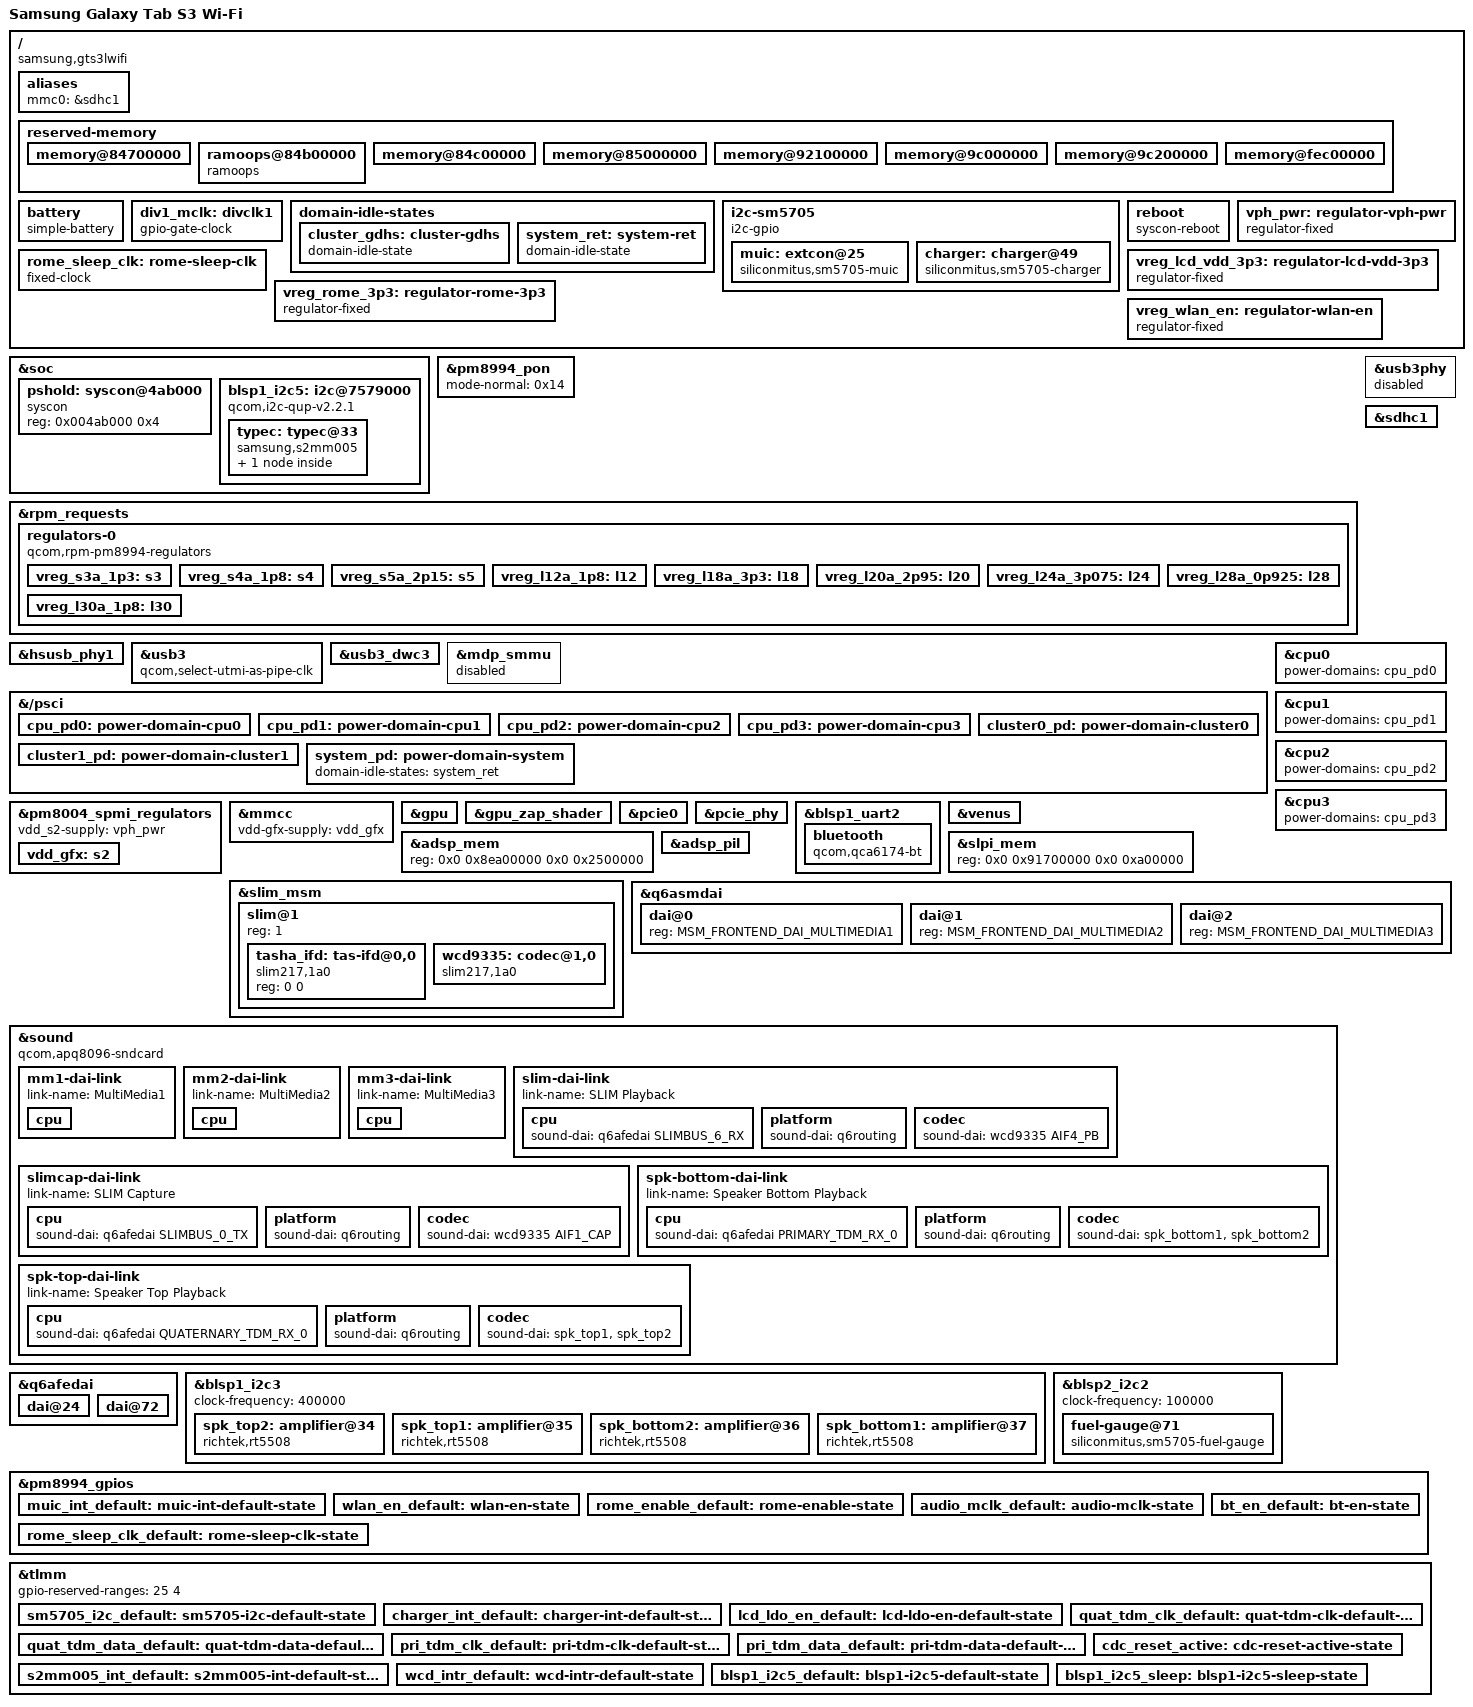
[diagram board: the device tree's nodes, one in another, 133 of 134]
// SPDX-License-Identifier: BSD-3-Clause
/*
 * Samsung Galaxy Tab S3 Wi-Fi (SM-T820), codename gts3lwifi, board rev 05
 *
 * SoC / PMIC set, from the live downstream DTB (qcom,pmic-id = <0x20009 0x1000c>):
 *   APQ8096 (msm-id 291) + PM8994 + PM8004. No PMI8994, no modem.
 * Internal storage: eMMC on SDHC1 (cmdline: androidboot.bootdevice=7464900.sdhci).
 *   UFS silicon is present but unpopulated; ufshc/ufsphy stay disabled.
 *
 * Working: eMMC, USB peripheral, reboot, GPU (headless, boot with
 * msm.separate_gpu_kms=1), Wi-Fi and Bluetooth (QCA6174), Venus, audio
 * (ADSP + WCD9335: headphones and microphones), SM5705 fuel gauge, charger
 * and MUIC, CPU/cluster/system idle. The panel, touch, speakers, sensors and
 * S-Pen are not here yet; the panel and touch have test DTs.
 *
 * GPU zap shader, Venus and ADSP firmware are Samsung-signed and come from
 * the device (apnhlos and modem partitions), under
 * qcom/apq8096/samsung/gts3lwifi/.
 *
 * Sources (all cross-checked against the live DTB with phandles resolved):
 *   downstream arch/arm64/boot/dts/samsung/msm8996-sec-gts3lwifi-r05.dts{,i}
 *   downstream arch/arm64/boot/dts/samsung/msm8996-pinctrl-sec-gts3lwifi-r05.dtsi
 *   downstream arch/arm64/boot/dts/samsung/msm8996-sec-common.dtsi
 *   downstream arch/arm64/boot/dts/samsung/msm8996-sm5705.dtsi
 *   downstream arch/arm64/boot/dts/qcom/msm8996-pm.dtsi (idle StateIDs)
 */

/dts-v1/;

#include <dt-bindings/gpio/gpio.h>
#include <dt-bindings/interrupt-controller/irq.h>
#include <dt-bindings/pinctrl/qcom,pmic-gpio.h>
#include <dt-bindings/sound/qcom,q6afe.h>
#include <dt-bindings/sound/qcom,q6asm.h>
#include <dt-bindings/sound/qcom,wcd9335.h>
#include "msm8996.dtsi"
#include "pm8994.dtsi"
#include "pm8004.dtsi"

/ {
	model = "Samsung Galaxy Tab S3 Wi-Fi";
	compatible = "samsung,gts3lwifi", "qcom,apq8096";
	chassis-type = "tablet";

	/*
	 * Bootloader DTB-selection IDs (documented in arm/qcom.yaml).
	 * lk2nd matches the root compatible instead, so these only matter
	 * if the DTB is ever offered to the stock bootloader.
	 */
	qcom,msm-id = <291 0x30001>;
	qcom,board-id = <8 5>;

	aliases {
		mmc0 = &sdhc1;
	};

	/*
	 * No memory@ node on purpose: msm8996.dtsi carries the placeholder
	 * and lk2nd rewrites it from the DDR partition table. The live DTB
	 * shows 0x80000000 + 2 GiB and 0x100000000 + 0x7e5e0000, i.e. 4 GiB
	 * with a hole - hardcoding a flat 4 GiB at 0x80000000 overshoots.
	 */

	/*
	 * Fixed regions from the downstream tree that msm8996.dtsi does not
	 * already cover. hyp/xbl/smem/tz (0x85800000-0x88800000) and the PIL
	 * regions (0x88800000-0x91700000) in msm8996.dtsi are subsets of the
	 * downstream removed/modem/peripheral carve-outs, so they are kept
	 * as they are and only the gaps are added here.
	 */
	reserved-memory {
		/* Downstream ss_plog@84700000 */
		memory@84700000 {
			reg = <0x0 0x84700000 0x0 0x400000>;
			no-map;
		};

		/* Same slot and layout as downstream ramoops@84B00000 */
		ramoops@84b00000 {
			compatible = "ramoops";
			reg = <0x0 0x84b00000 0x0 0x100000>;
			record-size = <0x40000>;
			console-size = <0x40000>;
			ftrace-size = <0x40000>;
			pmsg-size = <0x40000>;
		};

		/* Downstream lk_region@0 */
		memory@84c00000 {
			reg = <0x0 0x84c00000 0x0 0x400000>;
			no-map;
		};

		/*
		 * Samsung sec_debug: sec_dbg=0x1ff000@0x85000000 and
		 * sec_log=0x200000@0x85200000 on the downstream cmdline.
		 * S-Boot reads this back in upload mode, keep it untouched.
		 */
		memory@85000000 {
			reg = <0x0 0x85000000 0x0 0x400000>;
			no-map;
		};

		/*
		 * Tail of the downstream peripheral_region@8f400000
		 * (0x8f400000-0x92500000) not covered by msm8996.dtsi. adsp_mem
		 * is grown and slpi_mem moved into 0x91700000-0x92100000 below,
		 * so only the last 4 MiB are left.
		 */
		memory@92100000 {
			reg = <0x0 0x92100000 0x0 0x400000>;
			no-map;
		};

		/*
		 * The bootloader framebuffer (downstream cont_splash_mem,
		 * 0x9a400000, 28 MiB) is not reserved here: lk2nd adds its own
		 * reservation for it when lk2nd.pass-simplefb is used, and the
		 * two would overlap.
		 */

		/* Samsung TIMA (KNOX EL2), downstream tima_region@9C000000 */
		memory@9c000000 {
			reg = <0x0 0x9c000000 0x0 0x200000>;
			no-map;
		};

		/* Samsung RKP (KNOX EL2), downstream rkp_region@0x9C200000 */
		memory@9c200000 {
			reg = <0x0 0x9c200000 0x0 0xf00000>;
			no-map;
		};

		/* Pool handed to TrustZone, downstream qseecom_mem */
		memory@fec00000 {
			reg = <0x0 0xfec00000 0x0 0x1400000>;
			no-map;
		};
	};

	/*
	 * EB-BT825ABE, 6000 mAh, 3.85 V. Stock charges to 4.30 V
	 * (battery,chg_float_voltage), tops off at 300 mA, powers off
	 * around 3.4 V (battery0,tem_poff) and stops charging outside
	 * 0-50 C (battery,temp_{low,high}_threshold_normal).
	 */
	battery: battery {
		compatible = "simple-battery";
		device-chemistry = "lithium-ion";
		charge-full-design-microamp-hours = <6000000>;
		energy-full-design-microwatt-hours = <23100000>;
		voltage-min-design-microvolt = <3400000>;
		voltage-max-design-microvolt = <4300000>;
		constant-charge-voltage-max-microvolt = <4300000>;
		charge-term-current-microamp = <300000>;
		alert-celsius = <0 50>;
	};

	/* WCD9335 MCLK, 9.6 MHz: RPM div_clk1 out on PM8994 GPIO 15 */
	div1_mclk: divclk1 {
		compatible = "gpio-gate-clock";
		clocks = <&rpmcc RPM_SMD_DIV_CLK1>;
		#clock-cells = <0>;
		enable-gpios = <&pm8994_gpios 15 GPIO_ACTIVE_HIGH>;
		pinctrl-names = "default";
		pinctrl-0 = <&audio_mclk_default>;
	};

	/*
	 * Cluster and system idle, used through the PSCI power domains
	 * below. The firmware composes StateIDs the OSI way, like the
	 * downstream lpm-levels: power-down bit 30, affinity level at bit
	 * 24, system mode at bit 8, cluster mode at bit 4, CPU mode at bit 0.
	 * It grants L2 GDHS and system retention to the last CPU going down,
	 * with the CPUs in mode 4 without the power-down bit. It refuses the
	 * CPU power-down state (0x40000004, NOT_SUPPORTED), and with it L2
	 * power collapse (0x41000044, always DENIED). Latencies are on the
	 * safe side; downstream lists 90 and 350 us.
	 */
	domain-idle-states {
		cluster_gdhs: cluster-gdhs {
			compatible = "domain-idle-state";
			arm,psci-suspend-param = <0x01000034>;
			entry-latency-us = <200>;
			exit-latency-us = <300>;
			min-residency-us = <1000>;
		};

		system_ret: system-ret {
			compatible = "domain-idle-state";
			arm,psci-suspend-param = <0x02002334>;
			entry-latency-us = <400>;
			exit-latency-us = <700>;
			min-residency-us = <3000>;
		};
	};

	/*
	 * SM5705 charger and MUIC. Downstream bit-bangs this bus on TLMM 33
	 * (SDA) / 32 (SCL), which are HDMI DDC pins, not a BLSP pair. The
	 * fuel gauge of the same chip is on its own bus, see &blsp2_i2c2.
	 */
	i2c-sm5705 {
		compatible = "i2c-gpio";
		sda-gpios = <&tlmm 33 (GPIO_ACTIVE_HIGH | GPIO_OPEN_DRAIN)>;
		scl-gpios = <&tlmm 32 (GPIO_ACTIVE_HIGH | GPIO_OPEN_DRAIN)>;
		i2c-gpio,delay-us = <2>;
		pinctrl-names = "default";
		pinctrl-0 = <&sm5705_i2c_default>;
		#address-cells = <1>;
		#size-cells = <0>;

		/* USB charger type (BC1.2) */
		muic: extcon@25 {
			compatible = "siliconmitus,sm5705-muic";
			reg = <0x25>;
			interrupts-extended = <&pm8994_gpios 4 IRQ_TYPE_LEVEL_LOW>;
			pinctrl-names = "default";
			pinctrl-0 = <&muic_int_default>;
		};

		/*
		 * Charger and flash LED. Charging enable is PM8994 GPIO 13,
		 * active low; the bootloader leaves it low. Without a driver
		 * the charger keeps a 4.38 V charge voltage; the driver applies
		 * the battery's 4.30 V.
		 */
		charger: charger@49 {
			compatible = "siliconmitus,sm5705-charger";
			reg = <0x49>;
			interrupts-extended = <&tlmm 38 IRQ_TYPE_LEVEL_LOW>;
			pinctrl-names = "default";
			pinctrl-0 = <&charger_int_default>;
			monitored-battery = <&battery>;
			extcon = <&muic>;
			power-supplies = <&typec>;
		};
	};

	/*
	 * Restart. Samsung's TrustZone never returns from PSCI SYSTEM_RESET:
	 * the CPU stays stuck in the call, and about a minute later a secure
	 * watchdog leaves the tablet in a state that needs a forced restart.
	 * The vendor kernel never uses PSCI for this; it drops PS_HOLD
	 * (MPM2 PS_HOLD, 0x004ab000 bit 0, writable from Linux) and the PMIC
	 * resets. syscon-reboot does the same and, at its default priority
	 * (192), runs before the PSCI handler (129). pm8941-pwrkey programs
	 * the PMIC PS_HOLD reset type (hard reset) on a normal reboot.
	 */
	reboot {
		compatible = "syscon-reboot";
		regmap = <&pshold>;
		offset = <0x0>;
		mask = <0x1>;
		value = <0x0>;
	};

	/* QCA6174 sleep clock: PM8994 GPIO 18 function 2, see &pm8994_gpios */
	rome_sleep_clk: rome-sleep-clk {
		compatible = "fixed-clock";
		#clock-cells = <0>;
		clock-frequency = <32768>;
		clock-output-names = "rome_sleep_clk";
	};

	/* Battery / charger system rail, root of every PM8994 supply below */
	vph_pwr: regulator-vph-pwr {
		compatible = "regulator-fixed";
		regulator-name = "vph_pwr";
		regulator-min-microvolt = <3800000>;
		regulator-max-microvolt = <3800000>;
		regulator-always-on;
		regulator-boot-on;
	};

	/*
	 * SM57xx rails
	 * ------------
	 * None on this board feed USB, eMMC or the panel:
	 *  - SM5703 (msm8996-sm5703.dtsi) is only included by gts2llte,
	 *    never by any gts3lwifi/gts3llte revision.
	 *  - SM5705 (msm8996-sm5705.dtsi) is charger + MUIC + fuel gauge +
	 *    flash LED. The downstream defconfig does not set
	 *    CONFIG_REGULATOR_SM5705, no such driver exists in that tree,
	 *    and no *-supply anywhere resolves to an SM5705 node.
	 *  - USB PHYs: PM8994 L28 / L12 / L24. eMMC: PM8994 L20 / S4.
	 *    Panel VDD 3.3 V: external LDO gated by LCD_LDO_EN (TLMM 46),
	 *    modelled downstream as the fake regulator "ssreg-vdd".
	 * The only non-PMIC rail that therefore needs a stub is that LDO.
	 */
	vreg_lcd_vdd_3p3: regulator-lcd-vdd-3p3 {
		compatible = "regulator-fixed";
		regulator-name = "vreg_lcd_vdd_3p3";
		regulator-min-microvolt = <3300000>;
		regulator-max-microvolt = <3300000>;
		gpio = <&tlmm 46 GPIO_ACTIVE_HIGH>;
		enable-active-high;
		regulator-boot-on;
		regulator-always-on;
		vin-supply = <&vph_pwr>;
		pinctrl-names = "default";
		pinctrl-0 = <&lcd_ldo_en_default>;
	};

	/*
	 * QCA6174 ("Rome") Wi-Fi/BT power, from the downstream qcom,cnss
	 * node (cnss_wlan_en_vreg / rome_vreg), wired like the Xiaomi MSM8996
	 * boards: PM8994 GPIO 9 enables the 3.3 V supply, GPIO 8 is WLAN_EN.
	 *
	 * BT_EN (PM8994 GPIO 19) must be low while the 3.3 V rail comes up.
	 * The bootloader leaves it high; if the rail rises like that, Rome
	 * turns on its PCIe receiver after PERST# but never transmits (the
	 * root port sits in Polling.Compliance). So the 3.3 V regulator is
	 * not always-on: it starts off at probe, stays off for
	 * off-on-delay-us with BT_EN held low, and the PCIe driver switches
	 * it on through the WLAN_EN regulator.
	 */
	vreg_rome_3p3: regulator-rome-3p3 {
		compatible = "regulator-fixed";
		regulator-name = "vreg_rome_3p3";
		regulator-min-microvolt = <3300000>;
		regulator-max-microvolt = <3300000>;
		startup-delay-us = <4000>;
		off-on-delay-us = <1000000>;
		vin-supply = <&vph_pwr>;

		gpio = <&pm8994_gpios 9 GPIO_ACTIVE_HIGH>;
		enable-active-high;
		pinctrl-names = "default";
		pinctrl-0 = <&rome_enable_default>, <&bt_en_default>,
			    <&rome_sleep_clk_default>;
	};

	vreg_wlan_en: regulator-wlan-en {
		compatible = "regulator-fixed";
		regulator-name = "vreg_wlan_en";
		regulator-min-microvolt = <1800000>;
		regulator-max-microvolt = <1800000>;
		startup-delay-us = <70000>;
		vin-supply = <&vreg_rome_3p3>;

		gpio = <&pm8994_gpios 8 GPIO_ACTIVE_HIGH>;
		enable-active-high;
		pinctrl-names = "default";
		pinctrl-0 = <&wlan_en_default>;
	};
};

&soc {
	pshold: syscon@4ab000 {
		compatible = "syscon";
		reg = <0x004ab000 0x4>;
	};

	/*
	 * BLSP1 QUP5 I2C (TLMM 83 SDA, 84 SCL, downstream i2c_5), for the
	 * Type-C controller. msm8996.dtsi has no node for it; this one follows
	 * blsp1_i2c3/blsp1_i2c6 (QUP n: GIC SPI 94 + n, BAM channels 10 + 2n).
	 */
	blsp1_i2c5: i2c@7579000 {
		compatible = "qcom,i2c-qup-v2.2.1";
		reg = <0x07579000 0x1000>;
		interrupts = <GIC_SPI 99 IRQ_TYPE_LEVEL_HIGH>;
		clocks = <&gcc GCC_BLSP1_QUP5_I2C_APPS_CLK>,
			 <&gcc GCC_BLSP1_AHB_CLK>;
		clock-names = "core", "iface";
		pinctrl-names = "default", "sleep";
		pinctrl-0 = <&blsp1_i2c5_default>;
		pinctrl-1 = <&blsp1_i2c5_sleep>;
		dmas = <&blsp1_dma 20>, <&blsp1_dma 21>;
		dma-names = "tx", "rx";
		clock-frequency = <100000>;
		#address-cells = <1>;
		#size-cells = <0>;

		/*
		 * Samsung S2MM005 USB Type-C and PD controller. Its firmware
		 * negotiates the PD contract by itself; the charger takes its
		 * input limit from this supply too. Interrupt: open drain, low
		 * while an event is pending, pulled up on the board.
		 */
		typec: typec@33 {
			compatible = "samsung,s2mm005";
			reg = <0x33>;
			interrupts-extended = <&tlmm 73 IRQ_TYPE_LEVEL_LOW>;
			pinctrl-0 = <&s2mm005_int_default>;
			pinctrl-names = "default";

			connector {
				compatible = "usb-c-connector";
				label = "USB-C";
				power-role = "sink";
				data-role = "device";
			};
		};
	};
};

/*
 * Restart reasons as Samsung's bootloader reads them (vendor
 * PON_RESTART_REASON_*, stored in the PON spare register shifted by 2).
 * bootloader (0x02) and recovery (0x01) already match pm8994.dtsi;
 * NORMALBOOT (0x14) is what the vendor kernel writes on a plain reboot.
 */
&pm8994_pon {
	mode-normal = <0x14>;
};

/*
 * PM8994 rails via RPM. Only the rails consumed below are declared; the
 * parent-supply map follows apq8096-db820c.dts (PM8994 + no PMI8994 boost
 * bypass here, so the battery-fed LDO groups hang off vph_pwr directly).
 * Voltages match the downstream msm8996-regulator.dtsi / live DTB.
 */
&rpm_requests {
	regulators-0 {
		compatible = "qcom,rpm-pm8994-regulators";

		vdd_s1-supply = <&vph_pwr>;
		vdd_s2-supply = <&vph_pwr>;
		vdd_s3-supply = <&vph_pwr>;
		vdd_s4-supply = <&vph_pwr>;
		vdd_s5-supply = <&vph_pwr>;
		vdd_s6-supply = <&vph_pwr>;
		vdd_s7-supply = <&vph_pwr>;
		vdd_s8-supply = <&vph_pwr>;
		vdd_s9-supply = <&vph_pwr>;
		vdd_s10-supply = <&vph_pwr>;
		vdd_s11-supply = <&vph_pwr>;
		vdd_s12-supply = <&vph_pwr>;
		vdd_l2_l26_l28-supply = <&vreg_s3a_1p3>;
		vdd_l6_l12_l32-supply = <&vreg_s5a_2p15>;
		vdd_l8_l16_l30-supply = <&vph_pwr>;
		vdd_l9_l10_l18_l22-supply = <&vph_pwr>;
		vdd_l13_l19_l23_l24-supply = <&vph_pwr>;
		vdd_l20_l21-supply = <&vph_pwr>;
		vdd_lvs1_2-supply = <&vreg_s4a_1p8>;

		/* Also the QCA6174 1.3 V core, which ath10k does not manage */
		vreg_s3a_1p3: s3 {
			regulator-name = "vreg_s3a_1p3";
			regulator-min-microvolt = <1300000>;
			regulator-max-microvolt = <1300000>;
			regulator-always-on;
		};

		/*
		 * eMMC I/O rail; downstream marks it qcom,vdd-io-always-on.
		 * Also the WCD9335 and QCA6174 I/O supply.
		 */
		vreg_s4a_1p8: s4 {
			regulator-name = "vreg_s4a_1p8";
			regulator-min-microvolt = <1800000>;
			regulator-max-microvolt = <1800000>;
			regulator-always-on;
		};

		vreg_s5a_2p15: s5 {
			regulator-name = "vreg_s5a_2p15";
			regulator-min-microvolt = <2150000>;
			regulator-max-microvolt = <2150000>;
		};

		/* USB PHY PLL / core 1.8 V (downstream vdda18 / core-supply) */
		vreg_l12a_1p8: l12 {
			regulator-name = "vreg_l12a_1p8";
			regulator-min-microvolt = <1800000>;
			regulator-max-microvolt = <1800000>;
			regulator-allow-set-load;
		};

		/*
		 * 3.3 V on this board (downstream overrides msm8996's 2.7-2.9 V):
		 * touch controller analog supply (tsp_avdd), also requested by
		 * the downstream cnss node for the Wi-Fi antenna switch.
		 */
		vreg_l18a_3p3: l18 {
			regulator-name = "vreg_l18a_3p3";
			regulator-min-microvolt = <3300000>;
			regulator-max-microvolt = <3300000>;
			regulator-always-on;
		};

		/* eMMC flash rail; downstream marks it qcom,vdd-always-on */
		vreg_l20a_2p95: l20 {
			regulator-name = "vreg_l20a_2p95";
			regulator-min-microvolt = <2950000>;
			regulator-max-microvolt = <2950000>;
			regulator-allow-set-load;
			regulator-always-on;
		};

		/* USB2 PHY D+/D- 3.075 V (downstream vdda33) */
		vreg_l24a_3p075: l24 {
			regulator-name = "vreg_l24a_3p075";
			regulator-min-microvolt = <3075000>;
			regulator-max-microvolt = <3075000>;
		};

		/* USB PHY digital 0.925 V (downstream vdd-supply on both PHYs) */
		vreg_l28a_0p925: l28 {
			regulator-name = "vreg_l28a_0p925";
			regulator-min-microvolt = <925000>;
			regulator-max-microvolt = <925000>;
			regulator-allow-set-load;
		};

		/* QCA6174 crystal 1.8 V, not managed by ath10k */
		vreg_l30a_1p8: l30 {
			regulator-name = "vreg_l30a_1p8";
			regulator-min-microvolt = <1800000>;
			regulator-max-microvolt = <1800000>;
			regulator-always-on;
		};
	};
};

/*
 * USB
 * ---
 * Downstream: ssusb@6a00000 + dwc3@6a00000, maximum-speed "super-speed",
 * usb-phy = <qusb@7411000 ssphy@7410000>. The mainline equivalents are
 * usb3 (qcom,msm8996-dwc3) + usb3_dwc3, hsusb_phy1 (QUSB2, 0x7411000) and
 * usb3phy (QMP, 0x7410000).
 *
 * Bring-up goes high-speed only, on hsusb_phy1: SuperSpeed on this Type-C
 * port needs the s2mm005 CC/PD controller (BLSP1 QUP5 I2C, TLMM 83/84,
 * IRQ TLMM 73) for lane orientation plus the redriver enable on PM8994
 * GPIO 14 (downstream usb-notifier qcom,gpios_redriver_en), neither of
 * which has a mainline driver. usb3phy below keeps its supply routing
 * documented and stays disabled.
 *
 * TLMM: the downstream USB nodes reference no TLMM pinctrl state at all,
 * and the mainline usb3/PHY nodes need none, so there is nothing to add.
 *
 * On v6.19 msm8996.dtsi still uses the child-node form, which binds to
 * dwc3-qcom-legacy.c. That glue reads dr_mode from the child node and
 * forces the VBUS-valid override for every non-host mode, so no extcon or
 * role switch is needed to enumerate as a gadget; dr_mode = "peripheral"
 * additionally keeps the dwc3 core itself in device mode.
 */
&hsusb_phy1 {
	vdd-supply = <&vreg_l28a_0p925>;
	vdda-pll-supply = <&vreg_l12a_1p8>;
	vdda-phy-dpdm-supply = <&vreg_l24a_3p075>;
	status = "okay";
};

&usb3phy {
	vdda-phy-supply = <&vreg_l28a_0p925>;
	vdda-pll-supply = <&vreg_l12a_1p8>;
	status = "disabled";
};

&usb3 {
	/* usb3phy is off, so clock the core from UTMI instead of the pipe clock */
	qcom,select-utmi-as-pipe-clk;
	status = "okay";
};

&usb3_dwc3 {
	dr_mode = "peripheral";
	maximum-speed = "high-speed";
	phys = <&hsusb_phy1>;
	phy-names = "usb2-phy";
	snps,is-utmi-l1-suspend;
	snps,hird-threshold = /bits/ 8 <0>;
	snps,usb2-gadget-lpm-disable;
};

/*
 * eMMC (rootfs). Downstream sdhci@7464900: bus-width 8, HS400_1p8v /
 * HS200_1p8v / DDR_1p8v, vdd = PM8994 L20, vdd-io = PM8994 S4, both
 * always-on. sdc1_state_on / sdc1_state_off pinctrl comes from msm8996.dtsi.
 */
&sdhc1 {
	vmmc-supply = <&vreg_l20a_2p95>;
	vqmmc-supply = <&vreg_s4a_1p8>;
	mmc-hs400-1_8v;
	mmc-hs200-1_8v;
	status = "okay";
};

/*
 * Until the panel driver works, the display is driven by lk2nd's framebuffer
 * (lk2nd.pass-simplefb=autorefresh). The MDSS IOMMU driver gates its clock
 * after probing while the display engine still fetches through it, which
 * makes the firmware reset the tablet, so keep the kernel away from it.
 * TODO: re-enable together with the panel driver.
 */
&mdp_smmu {
	status = "disabled";
};

/*
 * CPU idle
 * --------
 * Hierarchical PSCI layout: CPU -> cluster (CPU0-1, CPU2-3) -> system,
 * with the msm8996.dtsi CPU state (0x4) per CPU and the states in
 * /domain-idle-states above. The firmware is in OSI mode from boot but
 * answers NOT_SUPPORTED to PSCI SET_SUSPEND_MODE, which cpuidle-psci-domain
 * accepts on msm8996/apq8096; without that the CPUs get no idle states.
 */
&{/psci} {
	cpu_pd0: power-domain-cpu0 {
		#power-domain-cells = <0>;
		power-domains = <&cluster0_pd>;
		domain-idle-states = <&cpu_sleep_0>;
	};

	cpu_pd1: power-domain-cpu1 {
		#power-domain-cells = <0>;
		power-domains = <&cluster0_pd>;
		domain-idle-states = <&cpu_sleep_0>;
	};

	cpu_pd2: power-domain-cpu2 {
		#power-domain-cells = <0>;
		power-domains = <&cluster1_pd>;
		domain-idle-states = <&cpu_sleep_0>;
	};

	cpu_pd3: power-domain-cpu3 {
		#power-domain-cells = <0>;
		power-domains = <&cluster1_pd>;
		domain-idle-states = <&cpu_sleep_0>;
	};

	cluster0_pd: power-domain-cluster0 {
		#power-domain-cells = <0>;
		power-domains = <&system_pd>;
		domain-idle-states = <&cluster_gdhs>;
	};

	cluster1_pd: power-domain-cluster1 {
		#power-domain-cells = <0>;
		power-domains = <&system_pd>;
		domain-idle-states = <&cluster_gdhs>;
	};

	system_pd: power-domain-system {
		#power-domain-cells = <0>;
		domain-idle-states = <&system_ret>;
	};
};

&cpu0 {
	/delete-property/ cpu-idle-states;
	power-domains = <&cpu_pd0>;
	power-domain-names = "psci";
};

&cpu1 {
	/delete-property/ cpu-idle-states;
	power-domains = <&cpu_pd1>;
	power-domain-names = "psci";
};

&cpu2 {
	/delete-property/ cpu-idle-states;
	power-domains = <&cpu_pd2>;
	power-domain-names = "psci";
};

&cpu3 {
	/delete-property/ cpu-idle-states;
	power-domains = <&cpu_pd3>;
	power-domain-names = "psci";
};

/*
 * GPU
 * ---
 * Adreno 530, headless while the panel is off: boot with
 * msm.separate_gpu_kms=1 so it gets its own DRM device without MDSS.
 * VDD_GFX is PM8004 S2 (downstream 400-1015 mV under GFX CPR). Mainline
 * has no GFX CPR, so pin it at the top corner like the Sony msm8996 boards.
 */
&pm8004_spmi_regulators {
	vdd_s2-supply = <&vph_pwr>;

	vdd_gfx: s2 {
		regulator-name = "vdd_gfx";
		regulator-min-microvolt = <1015000>;
		regulator-max-microvolt = <1015000>;
		regulator-always-on;
	};
};

&mmcc {
	vdd-gfx-supply = <&vdd_gfx>;
};

&gpu {
	status = "okay";
};

&gpu_zap_shader {
	firmware-name = "qcom/apq8096/samsung/gts3lwifi/a530_zap.mdt";
};

/*
 * Wi-Fi: QCA6174 on PCIe0 (ath10k), PERST# TLMM 35, WAKE# TLMM 37.
 * The PCIe driver switches WLAN_EN, which pulls in the 3.3 V rail.
 */
&pcie0 {
	vddpe-3v3-supply = <&vreg_wlan_en>;
	vdda-supply = <&vreg_l28a_0p925>;

	perst-gpios = <&tlmm 35 GPIO_ACTIVE_LOW>;
	wake-gpios = <&tlmm 37 GPIO_ACTIVE_HIGH>;

	status = "okay";
};

&pcie_phy {
	vdda-phy-supply = <&vreg_l28a_0p925>;
	vdda-pll-supply = <&vreg_l12a_1p8>;

	status = "okay";
};

/* Bluetooth: QCA6174 on BLSP1 UART2 (TLMM 41-44), BT_EN PM8994 GPIO 19 */
&blsp1_uart2 {
	label = "BT-UART";
	uart-has-rtscts;
	status = "okay";

	bluetooth {
		compatible = "qcom,qca6174-bt";
		enable-gpios = <&pm8994_gpios 19 GPIO_ACTIVE_HIGH>;
		clocks = <&rome_sleep_clk>;
	};
};

/*
 * Video: Venus with Samsung's signed firmware (PAS id 9). Its relocatable
 * segments fit msm8996.dtsi's venus_mem.
 */
&venus {
	firmware-name = "qcom/apq8096/samsung/gts3lwifi/venus.mdt";
	status = "okay";
};

/*
 * Audio
 * -----
 * ADSP with Samsung's signed firmware from the modem partition. Its
 * segments span 0x2100000 bytes, more than msm8996.dtsi's adsp_mem, so
 * adsp_mem grows to the start of gpu_mem and slpi_mem (unused) moves into
 * the tail of the downstream peripheral_region.
 *
 * WCD9335 on SLIMbus like apq8096-db820c: reset TLMM 74, one interrupt line
 * on TLMM 79, MCLK from PM8994 GPIO 15, all supplies PM8994 S4. Headphones
 * play through SLIMBUS_6_RX, the microphones record through SLIMBUS_0_TX;
 * the routing is in the UCM profile.
 *
 * Speakers: four Richtek RT5508 amplifiers on BLSP1 QUP3 I2C (TLMM 47/48,
 * downstream i2c_3). The bottom pair (0x36/0x37, USB end) is on the primary
 * TDM bus (TLMM 65 SCK, 66 WS, 68 SD1), the top pair (0x34/0x35) on the
 * quaternary one (TLMM 58 SCK, 59 WS, 61 SD1). Both run 4 slots of 16 bit
 * at 48 kHz (3.072 MHz) with a long, inverted frame sync from the SoC and
 * one bit of data delay, like stock. One stream feeds both buses (q6routing
 * routes MultiMedia1 to both ports).
 *
 * Measured on hardware with the amplifiers' report register (SPKRPTSEL 3,
 * the samples they receive): this ADSP fills a frame only with all 4 slots
 * active, and without a slot mapping (which it rejects for a port alone in
 * its group; stock never sends one) it places stream channels 32 bits
 * apart: channel 0 in slot 0, channel 1 in slot 2. So every amplifier plays
 * the first slot of a pair: pair 0 (slot 0) for the left channel, pair 1
 * (slot 2) for the right. In landscape with the home button on the right
 * (the keyboard cover's orientation) the top speakers are on the left: they
 * play the left channel, the bottom ones the right.
 */
&adsp_mem {
	reg = <0x0 0x8ea00000 0x0 0x2500000>;
};

&slpi_mem {
	reg = <0x0 0x91700000 0x0 0xa00000>;
};

&adsp_pil {
	firmware-name = "qcom/apq8096/samsung/gts3lwifi/adsp.mdt";
	status = "okay";
};

&slim_msm {
	status = "okay";

	slim@1 {
		reg = <1>;
		#address-cells = <2>;
		#size-cells = <0>;

		tasha_ifd: tas-ifd@0,0 {
			compatible = "slim217,1a0";
			reg = <0 0>;
		};

		wcd9335: codec@1,0 {
			compatible = "slim217,1a0";
			reg = <1 0>;

			clock-names = "mclk", "slimbus";
			clocks = <&div1_mclk>,
				 <&rpmcc RPM_SMD_BB_CLK1>;
			interrupt-parent = <&tlmm>;
			interrupts = <79 IRQ_TYPE_LEVEL_HIGH>;
			interrupt-names = "intr1";
			interrupt-controller;
			#interrupt-cells = <1>;

			pinctrl-0 = <&cdc_reset_active &wcd_intr_default>;
			pinctrl-names = "default";

			reset-gpios = <&tlmm 74 GPIO_ACTIVE_LOW>;
			slim-ifc-dev = <&tasha_ifd>;

			#sound-dai-cells = <1>;

			vdd-buck-supply = <&vreg_s4a_1p8>;
			vdd-buck-sido-supply = <&vreg_s4a_1p8>;
			vdd-tx-supply = <&vreg_s4a_1p8>;
			vdd-rx-supply = <&vreg_s4a_1p8>;
			vdd-io-supply = <&vreg_s4a_1p8>;
		};
	};
};

&q6asmdai {
	dai@0 {
		reg = <MSM_FRONTEND_DAI_MULTIMEDIA1>;
	};

	dai@1 {
		reg = <MSM_FRONTEND_DAI_MULTIMEDIA2>;
	};

	dai@2 {
		reg = <MSM_FRONTEND_DAI_MULTIMEDIA3>;
	};
};

&sound {
	compatible = "qcom,apq8096-sndcard";
	model = "Galaxy Tab S3";
	/*
	 * Downstream mic routing: AMIC1 <- MIC BIAS4 (third mic), AMIC2 <-
	 * MIC BIAS2 (headset mic), AMIC3 <- MIC BIAS1 (main mic), AMIC4 <-
	 * MIC BIAS3 (sub mic). In the wcd9335 driver only the RX DACs (via
	 * RX_BIAS) pull in MCLK, so a capture without a playback stream
	 * records digital silence. Hang the mic biases on MCLK as well.
	 */
	pinctrl-0 = <&pri_tdm_clk_default>, <&pri_tdm_data_default>,
		    <&quat_tdm_clk_default>, <&quat_tdm_data_default>;
	pinctrl-names = "default";

	audio-routing = "RX_BIAS", "MCLK",
			"MIC BIAS1", "MCLK",
			"MIC BIAS2", "MCLK",
			"MIC BIAS3", "MCLK",
			"MIC BIAS4", "MCLK",
			"AMIC1", "MIC BIAS4",
			"AMIC2", "MIC BIAS2",
			"AMIC3", "MIC BIAS1",
			"AMIC4", "MIC BIAS3";

	mm1-dai-link {
		link-name = "MultiMedia1";
		cpu {
			sound-dai = <&q6asmdai MSM_FRONTEND_DAI_MULTIMEDIA1>;
		};
	};

	mm2-dai-link {
		link-name = "MultiMedia2";
		cpu {
			sound-dai = <&q6asmdai MSM_FRONTEND_DAI_MULTIMEDIA2>;
		};
	};

	mm3-dai-link {
		link-name = "MultiMedia3";
		cpu {
			sound-dai = <&q6asmdai MSM_FRONTEND_DAI_MULTIMEDIA3>;
		};
	};

	slim-dai-link {
		link-name = "SLIM Playback";
		cpu {
			sound-dai = <&q6afedai SLIMBUS_6_RX>;
		};

		platform {
			sound-dai = <&q6routing>;
		};

		codec {
			sound-dai = <&wcd9335 AIF4_PB>;
		};
	};

	slimcap-dai-link {
		link-name = "SLIM Capture";
		cpu {
			sound-dai = <&q6afedai SLIMBUS_0_TX>;
		};

		platform {
			sound-dai = <&q6routing>;
		};

		codec {
			sound-dai = <&wcd9335 AIF1_CAP>;
		};
	};

	spk-bottom-dai-link {
		link-name = "Speaker Bottom Playback";
		cpu {
			sound-dai = <&q6afedai PRIMARY_TDM_RX_0>;
		};

		platform {
			sound-dai = <&q6routing>;
		};

		codec {
			sound-dai = <&spk_bottom1>, <&spk_bottom2>;
		};
	};

	spk-top-dai-link {
		link-name = "Speaker Top Playback";
		cpu {
			sound-dai = <&q6afedai QUATERNARY_TDM_RX_0>;
		};

		platform {
			sound-dai = <&q6routing>;
		};

		codec {
			sound-dai = <&spk_top1>, <&spk_top2>;
		};
	};
};

&q6afedai {
	dai@24 {
		reg = <PRIMARY_TDM_RX_0>;
		qcom,tdm-sync-mode = <1>;
		qcom,tdm-sync-src = <1>;
		qcom,tdm-data-out = <0>;
		qcom,tdm-invert-sync = <1>;
		qcom,tdm-data-delay = <1>;
		qcom,tdm-data-align = <0>;
	};

	dai@72 {
		reg = <QUATERNARY_TDM_RX_0>;
		qcom,tdm-sync-mode = <1>;
		qcom,tdm-sync-src = <1>;
		qcom,tdm-data-out = <0>;
		qcom,tdm-invert-sync = <1>;
		qcom,tdm-data-delay = <1>;
		qcom,tdm-data-align = <0>;
	};
};

&blsp1_i2c3 {
	clock-frequency = <400000>;
	status = "okay";

	spk_top2: amplifier@34 {
		compatible = "richtek,rt5508";
		reg = <0x34>;
		#sound-dai-cells = <0>;
		sound-name-prefix = "Top 2";
		richtek,channel-select = <0>;
		richtek,tdm-dac-slot = <0>;
	};

	spk_top1: amplifier@35 {
		compatible = "richtek,rt5508";
		reg = <0x35>;
		#sound-dai-cells = <0>;
		sound-name-prefix = "Top 1";
		richtek,channel-select = <0>;
		richtek,tdm-dac-slot = <0>;
	};

	spk_bottom2: amplifier@36 {
		compatible = "richtek,rt5508";
		reg = <0x36>;
		#sound-dai-cells = <0>;
		sound-name-prefix = "Bottom 2";
		richtek,channel-select = <0>;
		richtek,tdm-dac-slot = <1>;
	};

	spk_bottom1: amplifier@37 {
		compatible = "richtek,rt5508";
		reg = <0x37>;
		#sound-dai-cells = <0>;
		sound-name-prefix = "Bottom 1";
		richtek,channel-select = <0>;
		richtek,tdm-dac-slot = <1>;
	};
};

/*
 * SM5705 fuel gauge on TLMM 6 (SDA) / 7 (SCL). Downstream bit-bangs
 * these too, but they are the BLSP2 QUP2 I2C pins, so use the controller.
 * Its alert line (PM8994 GPIO 1) is not used; the driver polls.
 */
&blsp2_i2c2 {
	clock-frequency = <100000>;
	status = "okay";

	fuel-gauge@71 {
		compatible = "siliconmitus,sm5705-fuel-gauge";
		reg = <0x71>;
		monitored-battery = <&battery>;
		power-supplies = <&charger>;
	};
};

&pm8994_gpios {
	/* MUIC interrupt: push-pull 1.8 V output, idle high */
	muic_int_default: muic-int-default-state {
		pins = "gpio4";
		function = PMIC_GPIO_FUNC_NORMAL;
		input-enable;
		bias-pull-down;
		power-source = <PM8994_GPIO_S4>;
	};

	wlan_en_default: wlan-en-state {
		pins = "gpio8";
		function = PMIC_GPIO_FUNC_NORMAL;
		output-low;
		qcom,drive-strength = <PMIC_GPIO_STRENGTH_LOW>;
		power-source = <PM8994_GPIO_S4>;
		bias-disable;
	};

	rome_enable_default: rome-enable-state {
		pins = "gpio9";
		function = PMIC_GPIO_FUNC_NORMAL;
		output-low;
		qcom,drive-strength = <PMIC_GPIO_STRENGTH_LOW>;
		power-source = <PM8994_GPIO_S4>;
		bias-disable;
	};

	audio_mclk_default: audio-mclk-state {
		pins = "gpio15";
		function = PMIC_GPIO_FUNC_FUNC1;
		bias-disable;
		power-source = <PM8994_GPIO_S4>;
		qcom,drive-strength = <PMIC_GPIO_STRENGTH_LOW>;
	};

	rome_sleep_clk_default: rome-sleep-clk-state {
		pins = "gpio18";
		function = PMIC_GPIO_FUNC_FUNC2;
		bias-disable;
		power-source = <PM8994_GPIO_S4>;
	};

	bt_en_default: bt-en-state {
		pins = "gpio19";
		function = PMIC_GPIO_FUNC_NORMAL;
		output-low;
		qcom,drive-strength = <PMIC_GPIO_STRENGTH_LOW>;
		power-source = <PM8994_GPIO_S4>;
		bias-pull-down;
	};
};

&tlmm {
	/*
	 * Pins owned by Samsung's TrustZone. If Linux reads them, the firmware
	 * resets the tablet about 9 s into boot (confirmed on hardware).
	 *   25-28: BLSP1 QUP6 SPI, fingerprint sensor (downstream spi_6 / etspi)
	 * 58-61 (BLSP2 QUP4 SPI, the eSE SPI in the downstream pinctrl) are
	 * free on the Wi-Fi model: stock comments its eSE node out, and they
	 * carry the quaternary TDM bus to the top speakers.
	 */
	gpio-reserved-ranges = <25 4>;

	sm5705_i2c_default: sm5705-i2c-default-state {
		pins = "gpio32", "gpio33";
		function = "gpio";
		drive-strength = <2>;
		bias-disable;
	};

	charger_int_default: charger-int-default-state {
		pins = "gpio38";
		function = "gpio";
		drive-strength = <2>;
		bias-pull-up;
	};

	/* LCD_LDO_EN, from downstream mdss_dsi_active (gpio46) */
	lcd_ldo_en_default: lcd-ldo-en-default-state {
		pins = "gpio46";
		function = "gpio";
		drive-strength = <8>;
		bias-disable;
	};

	quat_tdm_clk_default: quat-tdm-clk-default-state {
		pins = "gpio58", "gpio59";
		function = "qua_mi2s";
		drive-strength = <8>;
		bias-disable;
	};

	quat_tdm_data_default: quat-tdm-data-default-state {
		pins = "gpio61";
		function = "qua_mi2s";
		drive-strength = <8>;
		bias-pull-down;
	};

	pri_tdm_clk_default: pri-tdm-clk-default-state {
		pins = "gpio65", "gpio66";
		function = "pri_mi2s";
		drive-strength = <8>;
		bias-disable;
	};

	pri_tdm_data_default: pri-tdm-data-default-state {
		pins = "gpio67", "gpio68";
		function = "pri_mi2s";
		drive-strength = <8>;
		bias-pull-down;
	};

	s2mm005_int_default: s2mm005-int-default-state {
		pins = "gpio73";
		function = "gpio";
		drive-strength = <2>;
		bias-disable;
		input-enable;
	};

	cdc_reset_active: cdc-reset-active-state {
		pins = "gpio74";
		function = "gpio";
		drive-strength = <16>;
		bias-disable;
		output-high;
	};

	wcd_intr_default: wcd-intr-default-state {
		pins = "gpio79";
		function = "gpio";
		drive-strength = <2>;
		bias-pull-down;
		input-enable;
	};

	blsp1_i2c5_default: blsp1-i2c5-default-state {
		pins = "gpio83", "gpio84";
		function = "blsp_i2c5";
		drive-strength = <6>;
		bias-disable;
	};

	blsp1_i2c5_sleep: blsp1-i2c5-sleep-state {
		pins = "gpio83", "gpio84";
		function = "gpio";
		drive-strength = <2>;
		bias-disable;
	};
};
